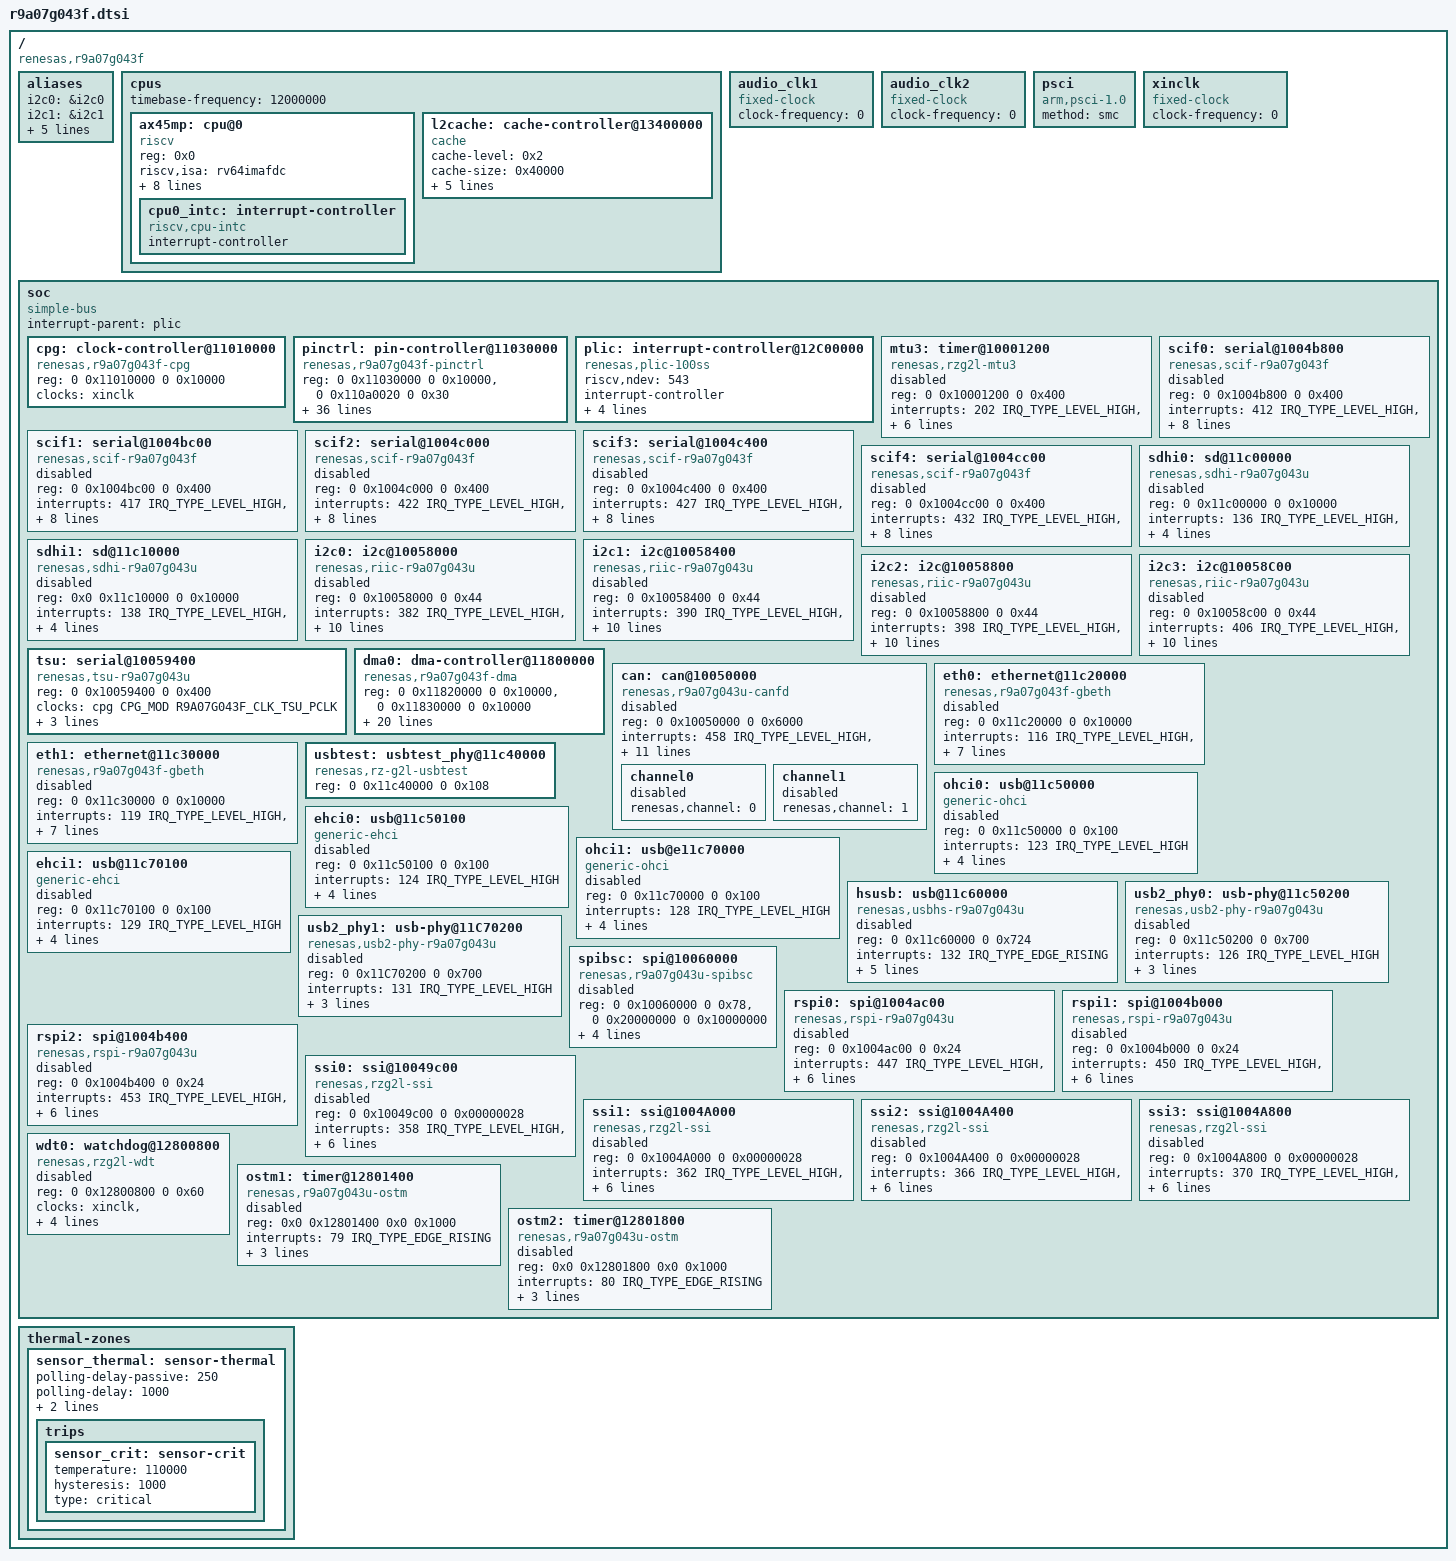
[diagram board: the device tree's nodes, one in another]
// SPDX-License-Identifier: GPL-2.0
/*
 * Device Tree Source for the RZ/Five  series (R9A07G043Fx) SoC
 *
 * Copyright (C) 2021 Renesas Electronics Corp.
 */


#include <dt-bindings/clock/r9a07g043f-cpg-mssr.h>
#include <dt-bindings/interrupt-controller/irq.h>

/ {
	compatible = "renesas,r9a07g043f";
	#address-cells = <2>;
	#size-cells = <2>;

	aliases {
		i2c0 = &i2c0;
		i2c1 = &i2c1;
		i2c2 = &i2c2;
		i2c3 = &i2c3;
		spi0 = &rspi0;
 		spi1 = &rspi1;
		spi2 = &rspi2;
	};

	cpus {
		#address-cells = <1>;
		#size-cells = <0>;
		timebase-frequency = <12000000>;

		ax45mp: cpu@0 {
			compatible = "riscv";
			device_type = "cpu";
			reg = <0x0>;
			status = "okay";
			riscv,isa = "rv64imafdc";
			riscv,priv-major = <0x1>;
			riscv,priv-minor = <0xa>;
			mmu-type = "riscv,sv39";
			i-cache-size = <0x8000>; // 32KB i-cache
			i-cache-line-size = <0x40>; // 64B cache line
			d-cache-size = <0x8000>; // 32KB d-cache
			d-cache-line-size = <0x40>; // 64B cache line
			next-level-cache = <&l2cache>;

			cpu0_intc: interrupt-controller {
				#interrupt-cells = <1>;
				compatible = "riscv,cpu-intc";
				interrupt-controller;
			};
		};

		l2cache: cache-controller@13400000 {
			compatible = "cache";
			cache-level = <0x2>;
			cache-size = <0x40000>; // 256KB l2-cache
			reg = <0x0 0x13400000 0x0 0x100000>; 
			andes,inst-prefetch = <0x0>; // 1
			andes,data-prefetch = <0x0>; // 
			andes,tag-ram-ctl = <0x1 0x0>;
			andes,data-ram-ctl = <0x1 0x0>;
		};

	};
    
	/*
     * The external audio clocks are configured as 0 Hz fixed frequency
     * clocks by default.
     * Boards that provide audio clocks should override them.
     */
	audio_clk1: audio_clk1 {
		compatible = "fixed-clock";
		#clock-cells = <0>;
		clock-frequency = <0>;
	};

	audio_clk2: audio_clk2 {
 		compatible = "fixed-clock";
		#clock-cells = <0>;
		clock-frequency = <0>;
	};

	psci {
		compatible = "arm,psci-1.0", "arm,psci-0.2";
		method = "smc";
	};

	xinclk: xinclk {
		compatible = "fixed-clock";
		#clock-cells = <0>;
		/* This value must be overridden by the board */
		clock-frequency = <0>;
	};

	soc: soc {
		compatible = "simple-bus";
		interrupt-parent = <&plic>;
		#address-cells = <2>;
		#size-cells = <2>;
		ranges;

		cpg: clock-controller@11010000 {
			compatible = "renesas,r9a07g043f-cpg";
			reg = <0 0x11010000 0 0x10000>;
			clocks = <&xinclk>;
			clock-names = "xinclk";
			#clock-cells = <2>;
			#reset-cells = <1>;
			#power-domain-cells = <0>;
		};

		pinctrl: pin-controller@11030000 {
			compatible = "renesas,r9a07g043f-pinctrl";
			reg = <0 0x11030000 0 0x10000>, <0 0x110a0020 0 0x30>;
			gpio-controller;
			#gpio-cells = <2>;
			gpio-ranges = <&pinctrl 0 0 392>;
			clocks = <&cpg CPG_MOD R9A07G043F_CLK_GPIO>;
			interrupt-controller;
			#interrupt-cells = <2>;
			interrupts =	<476 IRQ_TYPE_LEVEL_HIGH>,
					<477 IRQ_TYPE_LEVEL_HIGH>,
					<478 IRQ_TYPE_LEVEL_HIGH>,
					<479 IRQ_TYPE_LEVEL_HIGH>,
					<480 IRQ_TYPE_LEVEL_HIGH>,
					<481 IRQ_TYPE_LEVEL_HIGH>,
					<482 IRQ_TYPE_LEVEL_HIGH>,
					<483 IRQ_TYPE_LEVEL_HIGH>,
					<484 IRQ_TYPE_LEVEL_HIGH>,
					<485 IRQ_TYPE_LEVEL_HIGH>,
					<486 IRQ_TYPE_LEVEL_HIGH>,
					<487 IRQ_TYPE_LEVEL_HIGH>,
					<488 IRQ_TYPE_LEVEL_HIGH>,
					<489 IRQ_TYPE_LEVEL_HIGH>,
					<490 IRQ_TYPE_LEVEL_HIGH>,
					<491 IRQ_TYPE_LEVEL_HIGH>,
					<492 IRQ_TYPE_LEVEL_HIGH>,
					<493 IRQ_TYPE_LEVEL_HIGH>,
					<494 IRQ_TYPE_LEVEL_HIGH>,
					<495 IRQ_TYPE_LEVEL_HIGH>,
					<496 IRQ_TYPE_LEVEL_HIGH>,
					<497 IRQ_TYPE_LEVEL_HIGH>,
					<498 IRQ_TYPE_LEVEL_HIGH>,
					<499 IRQ_TYPE_LEVEL_HIGH>,
					<500 IRQ_TYPE_LEVEL_HIGH>,
					<501 IRQ_TYPE_LEVEL_HIGH>,
					<502 IRQ_TYPE_LEVEL_HIGH>,
					<503 IRQ_TYPE_LEVEL_HIGH>,
					<504 IRQ_TYPE_LEVEL_HIGH>,
					<505 IRQ_TYPE_LEVEL_HIGH>,
					<506 IRQ_TYPE_LEVEL_HIGH>,
					<507 IRQ_TYPE_LEVEL_HIGH>;
		};

		plic: interrupt-controller@12C00000 {
			compatible = "renesas,plic-100ss";
			#interrupt-cells = <2>;
			#address-cells = <0>;
			riscv,ndev = <543>;
			interrupt-controller;
			reg = <0x0 0x12C00000 0 0x400000>,
			      <0x0 0x13000000 0 0x400000>;
			clocks = <&cpg CPG_MOD R9A07G043F_CLK_NCEPLIC>;
			clock-names = "plic100ss";
			interrupts-extended = <
						&cpu0_intc 11 	// for target 0
						&cpu0_intc 9>;	 
		};

		mtu3: timer@10001200 {
			compatible = "renesas,rzg2l-mtu3";
			reg = <0 0x10001200 0 0x400>;
			interrupts =
				<202 IRQ_TYPE_LEVEL_HIGH>,
				<206 IRQ_TYPE_LEVEL_HIGH>,
				<209 IRQ_TYPE_LEVEL_HIGH>,
				<213 IRQ_TYPE_LEVEL_HIGH>;
			interrupt-names = "tgi0a" , "tci0v" , "tgi1a" , "tgi2a";
			clocks = <&cpg CPG_MOD R9A07G043F_CLK_MTU>;
			clock-names = "fck";
			power-domains = <&cpg>;
			resets = <&cpg R9A07G043F_CLK_MTU>;
			status = "disabled";
		};

		scif0: serial@1004b800 {
			compatible = "renesas,scif-r9a07g043f";
			reg = <0 0x1004b800 0 0x400>;
			interrupts =
				<412 IRQ_TYPE_LEVEL_HIGH>,
				<414 IRQ_TYPE_LEVEL_HIGH>,
				<415 IRQ_TYPE_LEVEL_HIGH>,
				<413 IRQ_TYPE_LEVEL_HIGH>,
				<416 IRQ_TYPE_LEVEL_HIGH>,
				<416 IRQ_TYPE_LEVEL_HIGH>;
			clocks = <&cpg CPG_MOD R9A07G043F_CLK_SCIF0>;
			clock-names = "fck";
			resets = <&cpg R9A07G043F_CLK_SCIF0>;
			power-domains = <&cpg>;
			status = "disable";
		};

		scif1: serial@1004bc00 {
			compatible = "renesas,scif-r9a07g043f";
			reg = <0 0x1004bc00 0 0x400>;
			interrupts =
				<417 IRQ_TYPE_LEVEL_HIGH>,
				<419 IRQ_TYPE_LEVEL_HIGH>,
				<420 IRQ_TYPE_LEVEL_HIGH>,
				<418 IRQ_TYPE_LEVEL_HIGH>,
				<421 IRQ_TYPE_LEVEL_HIGH>,
				<421 IRQ_TYPE_LEVEL_HIGH>;
			clocks = <&cpg CPG_MOD R9A07G043F_CLK_SCIF1>;
			clock-names = "fck";
			resets = <&cpg R9A07G043F_CLK_SCIF1>;
			power-domains = <&cpg>;
			status = "disable";
		};

		scif2: serial@1004c000 {
			compatible = "renesas,scif-r9a07g043f";
			reg = <0 0x1004c000 0 0x400>;
			interrupts =
				<422 IRQ_TYPE_LEVEL_HIGH>,
				<424 IRQ_TYPE_LEVEL_HIGH>,
				<425 IRQ_TYPE_LEVEL_HIGH>,
				<423 IRQ_TYPE_LEVEL_HIGH>,
				<426 IRQ_TYPE_LEVEL_HIGH>,
				<426 IRQ_TYPE_LEVEL_HIGH>;
			clocks = <&cpg CPG_MOD R9A07G043F_CLK_SCIF2>;
			clock-names = "fck";
			resets = <&cpg R9A07G043F_CLK_SCIF2>;
			power-domains = <&cpg>;
			status = "disable";
		};

		scif3: serial@1004c400 {
			compatible = "renesas,scif-r9a07g043f";
			reg = <0 0x1004c400 0 0x400>;
			interrupts =
				<427 IRQ_TYPE_LEVEL_HIGH>,
				<429 IRQ_TYPE_LEVEL_HIGH>,
				<430 IRQ_TYPE_LEVEL_HIGH>,
				<428 IRQ_TYPE_LEVEL_HIGH>,
				<431 IRQ_TYPE_LEVEL_HIGH>,
				<431 IRQ_TYPE_LEVEL_HIGH>;
			clocks = <&cpg CPG_MOD R9A07G043F_CLK_SCIF3>;
			clock-names = "fck";
			resets = <&cpg R9A07G043F_CLK_SCIF3>;
			power-domains = <&cpg>;
			status = "disable";
		};

		scif4: serial@1004cc00 {
			compatible = "renesas,scif-r9a07g043f";
			reg = <0 0x1004cc00 0 0x400>;
			interrupts =
				<432 IRQ_TYPE_LEVEL_HIGH>,
				<434 IRQ_TYPE_LEVEL_HIGH>,
				<435 IRQ_TYPE_LEVEL_HIGH>,
				<433 IRQ_TYPE_LEVEL_HIGH>,
				<436 IRQ_TYPE_LEVEL_HIGH>,
				<436 IRQ_TYPE_LEVEL_HIGH>;
			clocks = <&cpg CPG_MOD R9A07G043F_CLK_SCIF4>;
			clock-names = "fck";
			resets = <&cpg R9A07G043F_CLK_SCIF4>;
			power-domains = <&cpg>;
			status = "disable";
		};

		sdhi0: sd@11c00000 {
			compatible = "renesas,sdhi-r9a07g043u",
				     "renesas,rcar-gen3-sdhi";
			reg = <0 0x11c00000 0 0x10000>;
			interrupts = <136 IRQ_TYPE_LEVEL_HIGH>,
				     <137 IRQ_TYPE_LEVEL_HIGH>;
			clocks = <&cpg CPG_MOD R9A07G043F_CLK_SDHI0>;
			resets = <&cpg R9A07G043F_CLK_SDHI0>;
			power-domains = <&cpg>;
			status = "disabled";
		};

		sdhi1: sd@11c10000 {
			compatible = "renesas,sdhi-r9a07g043u",
				     "renesas,rcar-gen3-sdhi";
			reg = <0x0 0x11c10000 0 0x10000>;
			interrupts = <138 IRQ_TYPE_LEVEL_HIGH>,
				     <139 IRQ_TYPE_LEVEL_HIGH>;
			clocks = <&cpg CPG_MOD R9A07G043F_CLK_SDHI1>;
			resets = <&cpg R9A07G043F_CLK_SDHI1>;
			power-domains = <&cpg>;
			status = "disabled";
		};

		i2c0: i2c@10058000 {
			#address-cells = <1>;
			#size-cells = <0>;
			compatible = "renesas,riic-r9a07g043u",
					"renesas,riic-rz";
			reg = <0 0x10058000 0 0x44>;
			interrupts = <382  IRQ_TYPE_LEVEL_HIGH>,
				     <380 IRQ_TYPE_EDGE_RISING>,
				     <381 IRQ_TYPE_EDGE_RISING>,
				     <384 IRQ_TYPE_LEVEL_HIGH>,
				     <385 IRQ_TYPE_LEVEL_HIGH>,
				     <383 IRQ_TYPE_LEVEL_HIGH>,
				     <386 IRQ_TYPE_LEVEL_HIGH>,
				     <387 IRQ_TYPE_LEVEL_HIGH>;
			clocks = <&cpg CPG_MOD R9A07G043F_CLK_I2C0>;
			clock-frequency = <100000>;
			resets = <&cpg R9A07G043F_CLK_I2C0>;
			status = "disabled";
		};

		i2c1: i2c@10058400 {
			#address-cells = <1>;
			#size-cells = <0>;
			compatible = "renesas,riic-r9a07g043u",
					"renesas,riic-rz";
			reg = <0 0x10058400 0 0x44>;
			interrupts = <390  IRQ_TYPE_LEVEL_HIGH>,
				     <388 IRQ_TYPE_EDGE_RISING>,
				     <389 IRQ_TYPE_EDGE_RISING>,
				     <392 IRQ_TYPE_LEVEL_HIGH>,
				     <393 IRQ_TYPE_LEVEL_HIGH>,
				     <391 IRQ_TYPE_LEVEL_HIGH>,
				     <394 IRQ_TYPE_LEVEL_HIGH>,
				     <395 IRQ_TYPE_LEVEL_HIGH>;
			clocks = <&cpg CPG_MOD R9A07G043F_CLK_I2C1>;
			clock-frequency = <100000>;
			resets = <&cpg R9A07G043F_CLK_I2C1>;
			status = "disabled";
		};

		i2c2: i2c@10058800 {
			#address-cells = <1>;
			#size-cells = <0>;
			compatible = "renesas,riic-r9a07g043u",
					"renesas,riic-rz";
			reg = <0 0x10058800 0 0x44>;
			interrupts = <398  IRQ_TYPE_LEVEL_HIGH>,
				     <396 IRQ_TYPE_EDGE_RISING>,
				     <397 IRQ_TYPE_EDGE_RISING>,
				     <400 IRQ_TYPE_LEVEL_HIGH>,
				     <401 IRQ_TYPE_LEVEL_HIGH>,
				     <399 IRQ_TYPE_LEVEL_HIGH>,
				     <402 IRQ_TYPE_LEVEL_HIGH>,
				     <403 IRQ_TYPE_LEVEL_HIGH>;
			clocks = <&cpg CPG_MOD R9A07G043F_CLK_I2C2>;
			clock-frequency = <100000>;
			resets = <&cpg R9A07G043F_CLK_I2C2>;
			status = "disabled";
		};

		i2c3: i2c@10058C00 {
			#address-cells = <1>;
			#size-cells = <0>;
			compatible = "renesas,riic-r9a07g043u",
					"renesas,riic-rz";
			reg = <0 0x10058c00 0 0x44>;
			interrupts = <406  IRQ_TYPE_LEVEL_HIGH>,
				     <404 IRQ_TYPE_EDGE_RISING>,
				     <405 IRQ_TYPE_EDGE_RISING>,
				     <408 IRQ_TYPE_LEVEL_HIGH>,
				     <409 IRQ_TYPE_LEVEL_HIGH>,
				     <407 IRQ_TYPE_LEVEL_HIGH>,
				     <410 IRQ_TYPE_LEVEL_HIGH>,
				     <411 IRQ_TYPE_LEVEL_HIGH>;
			clocks = <&cpg CPG_MOD R9A07G043F_CLK_I2C3>;
			clock-frequency = <100000>;
			resets = <&cpg R9A07G043F_CLK_I2C3>;
			status = "disabled";
		};

		tsu: serial@10059400 {
			compatible = "renesas,tsu-r9a07g043u";
			reg = <0 0x10059400 0 0x400>;
			clocks = <&cpg CPG_MOD R9A07G043F_CLK_TSU_PCLK>;
			resets = <&cpg R9A07G043F_CLK_TSU_PCLK>;
			clock-names = "tsu";
			thermal-cal = <1>;
			#thermal-sensor-cells = <0>;
			power-domains = <&cpg>;
		};

		dma0: dma-controller@11800000 {
			compatible = "renesas,r9a07g043f-dma",
				"renesas,rz-dmac";
			reg =   <0 0x11820000 0 0x10000>,
				<0 0x11830000 0 0x10000>;

			interrupts =
				<173 IRQ_TYPE_EDGE_RISING>,    
				<157 IRQ_TYPE_EDGE_RISING>,
				<158 IRQ_TYPE_EDGE_RISING>,
				<159 IRQ_TYPE_EDGE_RISING>,
				<160 IRQ_TYPE_EDGE_RISING>,
				<161 IRQ_TYPE_EDGE_RISING>,
				<162 IRQ_TYPE_EDGE_RISING>,
				<163 IRQ_TYPE_EDGE_RISING>,
				<164 IRQ_TYPE_EDGE_RISING>,
				<165 IRQ_TYPE_EDGE_RISING>,
				<166 IRQ_TYPE_EDGE_RISING>,
				<167 IRQ_TYPE_EDGE_RISING>,
				<168 IRQ_TYPE_EDGE_RISING>,
				<169 IRQ_TYPE_EDGE_RISING>,
				<170 IRQ_TYPE_EDGE_RISING>,
				<171 IRQ_TYPE_EDGE_RISING>,
				<172 IRQ_TYPE_EDGE_RISING>;
			interrupt-names = "error", 
				"ch0", "ch1", "ch2", "ch3",
				"ch4", "ch5", "ch6", "ch7",
				"ch8", "ch9", "ch10", "ch11",
				"ch12", "ch13", "ch14", "ch15";
			dma-channels = <16>;
			#dma-cells = <1>;
			clocks = <&cpg CPG_MOD R9A07G043F_CLK_DMAC>;
			resets = <&cpg R9A07G043F_CLK_DMAC>;
		};

		can: can@10050000 {
			compatible = "renesas,r9a07g043u-canfd";
			reg = <0 0x10050000 0 0x6000>;
			interrupts =    <458 IRQ_TYPE_LEVEL_HIGH>,
					<454 IRQ_TYPE_LEVEL_HIGH>,
					<460 IRQ_TYPE_LEVEL_HIGH>,
					<455 IRQ_TYPE_LEVEL_HIGH>,
					<461 IRQ_TYPE_LEVEL_HIGH>,
					<456 IRQ_TYPE_LEVEL_HIGH>,
					<457 IRQ_TYPE_LEVEL_HIGH>,
					<459 IRQ_TYPE_LEVEL_HIGH>;

			clocks = <&cpg CPG_MOD R9A07G043F_CLK_CANFD>,
				 <&cpg CPG_CORE R9A07G043F_CLK_P0>;
			clock-names = "fck","canfd";
			resets = <&cpg R9A07G043F_CLK_CANFD>;
			power-dmains = <&cpg>;
			status = "disabled";
			channel0 {
				renesas,channel = <0>;
				status = "disabled";
			};
			channel1 {
				renesas,channel = <1>;
				status = "disabled";
			};
		};

		eth0: ethernet@11c20000 {
			compatible = "renesas,r9a07g043f-gbeth",
				     "renesas,rzg2l-gbeth";
			reg = <0 0x11c20000 0 0x10000>;
			interrupts = <116 IRQ_TYPE_LEVEL_HIGH>,
				     <117 IRQ_TYPE_LEVEL_HIGH>,
				     <118 IRQ_TYPE_LEVEL_HIGH>;
			interrupt-names = "mux", "fil", "arp_ns";
			clocks = <&cpg CPG_MOD R9A07G043F_CLK_ETH0>;
			resets = <&cpg R9A07G043F_CLK_ETH0>;
			power-domains = <&cpg>;
			phy-mode = "rgmii";
			#address-cells = <1>;
			#size-cells = <0>;
			eth-pin-mode-switch = <&pinctrl 0>;
			status = "disabled";
		};

		eth1: ethernet@11c30000 {
			compatible = "renesas,r9a07g043f-gbeth",
				     "renesas,rzg2l-gbeth";
			reg = <0 0x11c30000 0 0x10000>;
			interrupts = <119 IRQ_TYPE_LEVEL_HIGH>,
				     <120 IRQ_TYPE_LEVEL_HIGH>,
				     <121 IRQ_TYPE_LEVEL_HIGH>;
			interrupt-names = "mux", "fil", "arp_ns";
			clocks = <&cpg CPG_MOD R9A07G043F_CLK_ETH1>;
			resets = <&cpg R9A07G043F_CLK_ETH1>;
			power-domains = <&cpg>;
			phy-mode = "rgmii";
			#address-cells = <1>;
			#size-cells = <0>;
			eth-pin-mode-switch = <&pinctrl 1>;
			status = "disabled";
		};

		usbtest: usbtest_phy@11c40000 {
			compatible = "renesas,rz-g2l-usbtest";
			reg = <0 0x11c40000 0 0x108>;
			#phy-cells = <0>;
		};

		ohci0: usb@11c50000 {
			compatible = "generic-ohci";
			reg = <0 0x11c50000 0 0x100>;
			interrupts = <123 IRQ_TYPE_LEVEL_HIGH>;
			clocks = <&cpg CPG_MOD R9A07G043F_CLK_USB0>;
			resets = <&cpg R9A07G043F_CLK_USB0>;
			phys = <&usbtest>, <&usb2_phy0>;
			phy-names = "usb";
			power-domains = <&cpg>;
			status = "disabled";
		};

		ehci0: usb@11c50100 {
			compatible = "generic-ehci";
			reg = <0 0x11c50100 0 0x100>;
			interrupts = <124 IRQ_TYPE_LEVEL_HIGH>;
			clocks = <&cpg CPG_MOD R9A07G043F_CLK_USB0>;
			resets = <&cpg R9A07G043F_CLK_USB0>;
			phys = <&usbtest>, <&usb2_phy0>;
			phy-names = "usb";
			power-domains = <&cpg>;
			status = "disabled";
		};

		ohci1: usb@e11c70000 {
			compatible = "generic-ohci";
			reg = <0 0x11c70000 0 0x100>;
			interrupts = <128 IRQ_TYPE_LEVEL_HIGH>;
			clocks = <&cpg CPG_MOD R9A07G043F_CLK_USB1>;
			resets = <&cpg R9A07G043F_CLK_USB1>;
			phys = <&usbtest>, <&usb2_phy1>;
			phy-names = "usb";
			power-domains = <&cpg>;
			status = "disabled";
		};

		ehci1: usb@11c70100 {
			compatible = "generic-ehci";
			reg = <0 0x11c70100 0 0x100>;
			interrupts = <129 IRQ_TYPE_LEVEL_HIGH>;
			clocks = <&cpg CPG_MOD R9A07G043F_CLK_USB1>;
			resets = <&cpg R9A07G043F_CLK_USB1>;
			phys = <&usbtest>, <&usb2_phy1>;
			phy-names = "usb";
			power-domains = <&cpg>;
			status = "disabled";
		};

		hsusb: usb@11c60000 {
			compatible = "renesas,usbhs-r9a07g043u",
				     "renesas,g2l-usbhs";
			reg = <0 0x11c60000 0 0x724>;
			interrupts = <132 IRQ_TYPE_EDGE_RISING>;
			clocks = <&cpg CPG_MOD R9A07G043F_CLK_USB0>;
			resets = <&cpg R9A07G043F_CLK_USB0>;
			renesas,buswait = <7>;
			phys = <&usbtest>, <&usb2_phy0>;
			phy-names = "usb";
			power-domains = <&cpg>;
			status = "disabled";
		};

		usb2_phy0: usb-phy@11c50200 {
			compatible = "renesas,usb2-phy-r9a07g043u",
				     "renesas,rcar-gen3-usb2-phy";
			reg = <0 0x11c50200 0 0x700>;
			interrupts = <126 IRQ_TYPE_LEVEL_HIGH>;
			clocks = <&cpg CPG_MOD R9A07G043F_CLK_USB0>;
			power-domains = <&cpg>;
			resets = <&cpg R9A07G043F_CLK_USB0>;
			#phy-cells = <0>;
			status = "disabled";
		};

		usb2_phy1: usb-phy@11C70200 {
			compatible = "renesas,usb2-phy-r9a07g043u",
				     "renesas,rcar-gen3-usb2-phy";
			reg = <0 0x11C70200 0 0x700>;
			interrupts = <131 IRQ_TYPE_LEVEL_HIGH>;
			clocks = <&cpg CPG_MOD R9A07G043F_CLK_USB1>;
			power-domains = <&cpg>;
			resets = <&cpg R9A07G043F_CLK_USB1>;
			#phy-cells = <0>;
			status = "disabled";
		};

		spibsc: spi@10060000 {
			compatible = "renesas,r9a07g043u-spibsc";
			reg = <0 0x10060000 0 0x78>,
			      <0 0x20000000 0 0x10000000>;
			interrupts = <73 IRQ_TYPE_LEVEL_HIGH>;
			clocks = <&cpg CPG_MOD R9A07G043F_CLK_SPI>;
			resets = <&cpg R9A07G043F_CLK_SPI>;
			power-domains = <&cpg>;
			#address-cells = <1>;
			#size-cells = <0>;
			status = "disabled";
		};

		rspi0: spi@1004ac00 {
			#address-cells = <1>;
			#size-cells = <0>;
			compatible = "renesas,rspi-r9a07g043u",
				     "renesas,rspi-rz";
			reg = <0 0x1004ac00 0 0x24>;
			interrupts = <447 IRQ_TYPE_LEVEL_HIGH>,
				     <445 IRQ_TYPE_LEVEL_HIGH>,
				     <446 IRQ_TYPE_LEVEL_HIGH>;
			interrupt-names = "error", "rx", "tx";
			clocks = <&cpg CPG_MOD R9A07G043F_CLK_RSPI0>;
			resets = <&cpg R9A07G043F_CLK_RSPI0>;
			power-domains = <&cpg>;
			num-cs = <1>;
			status = "disabled";
		};

		rspi1: spi@1004b000 {
			#address-cells = <1>;
			#size-cells = <0>;
			compatible = "renesas,rspi-r9a07g043u",
				     "renesas,rspi-rz";
			reg = <0 0x1004b000 0 0x24>;
			interrupts = <450 IRQ_TYPE_LEVEL_HIGH>,
				     <448 IRQ_TYPE_LEVEL_HIGH>,
				     <449 IRQ_TYPE_LEVEL_HIGH>;
			interrupt-names = "error", "rx", "tx";
			clocks = <&cpg CPG_MOD R9A07G043F_CLK_RSPI1>;
			resets = <&cpg R9A07G043F_CLK_RSPI1>;
			power-domains = <&cpg>;
			num-cs = <1>;
			status = "disabled";
		};

		rspi2: spi@1004b400 {
			#address-cells = <1>;
			#size-cells = <0>;
			compatible = "renesas,rspi-r9a07g043u",
				     "renesas,rspi-rz";
			reg = <0 0x1004b400 0 0x24>;
			interrupts = <453 IRQ_TYPE_LEVEL_HIGH>,
				     <451 IRQ_TYPE_LEVEL_HIGH>,
				     <452 IRQ_TYPE_LEVEL_HIGH>;
			interrupt-names = "error", "rx", "tx";
			clocks = <&cpg CPG_MOD R9A07G043F_CLK_RSPI2>;
			resets = <&cpg R9A07G043F_CLK_RSPI2>;
			power-domains = <&cpg>;
			num-cs = <1>;
			status = "disabled";
		};

		ssi0: ssi@10049c00 {
			#sound-dai-cells = <0>;
			compatible = "renesas,rzg2l-ssi";
			reg = <0 0x10049c00 0 0x00000028>;
			interrupts = <358 IRQ_TYPE_LEVEL_HIGH>,
				     <359 IRQ_TYPE_EDGE_RISING>,
				     <360 IRQ_TYPE_EDGE_RISING>;
			interrupt-names = "int", "rx", "tx";
			clocks = <&cpg CPG_MOD R9A07G043F_CLK_SSI0> ,
				 <&audio_clk1>,
				 <&audio_clk2>;
			clock-names = "ssi", "audio_clk1", "audio_clk2";
			resets = <&cpg R9A07G043F_CLK_SSI0>;
			power-domains = <&cpg>;
			status = "disabled";
		};

		ssi1: ssi@1004A000 {
			#sound-dai-cells = <0>;
			compatible = "renesas,rzg2l-ssi";
			reg = <0 0x1004A000 0 0x00000028>;
			interrupts = <362 IRQ_TYPE_LEVEL_HIGH>,
				     <363 IRQ_TYPE_EDGE_RISING>,
				     <364 IRQ_TYPE_EDGE_RISING>;
			interrupt-names = "int", "rx", "tx";
			clocks = <&cpg CPG_MOD R9A07G043F_CLK_SSI1>,
				 <&audio_clk1>,
				 <&audio_clk2>;
			clock-names = "ssi", "audio_clk1", "audio_clk2";
			resets = <&cpg R9A07G043F_CLK_SSI1>;
			power-domains = <&cpg>;
			status = "disabled";
		};

		ssi2: ssi@1004A400 {
			#sound-dai-cells = <0>;
			compatible = "renesas,rzg2l-ssi";
			reg = <0 0x1004A400 0 0x00000028>;
			interrupts = <366 IRQ_TYPE_LEVEL_HIGH>,
				     <367 IRQ_TYPE_EDGE_RISING>,
				     <368 IRQ_TYPE_EDGE_RISING>;
			interrupt-names = "int", "rx", "tx";
			clocks = <&cpg CPG_MOD R9A07G043F_CLK_SSI2>,
				 <&audio_clk1>,
				 <&audio_clk2>;
			clock-names = "ssi", "audio_clk1", "audio_clk2";
			resets = <&cpg R9A07G043F_CLK_SSI2>;
			power-domains = <&cpg>;
			status = "disabld";
		};

		ssi3: ssi@1004A800 {
			#sound-dai-cells = <0>;
			compatible = "renesas,rzg2l-ssi";
			reg = <0 0x1004A800 0 0x00000028>;
			interrupts = <370 IRQ_TYPE_LEVEL_HIGH>,
				     <371 IRQ_TYPE_EDGE_RISING>,
				     <372 IRQ_TYPE_EDGE_RISING>;
			interrupt-names = "int", "rx", "tx";
			clocks = <&cpg CPG_MOD R9A07G043F_CLK_SSI3>,
				 <&audio_clk1>,
				 <&audio_clk2>;
			clock-names = "ssi", "audio_clk1", "audio_clk2";
			resets = <&cpg R9A07G043F_CLK_SSI3>;
			power-domains = <&cpg>;
			status = "disabled";
		};

		wdt0: watchdog@12800800 {
			compatible = "renesas,rzg2l-wdt";
			reg = <0 0x12800800 0 0x60>;
			clocks = <&xinclk>,
				 <&cpg CPG_MOD R9A07G043F_CLK_WDT0>;
			interrupts = <81 IRQ_TYPE_LEVEL_HIGH>,
				     <82 IRQ_TYPE_LEVEL_HIGH>;
			resets = <&cpg R9A07G043F_CLK_WDT0>;
			status = "disabled";
		};

		ostm1: timer@12801400 {
			compatible = "renesas,r9a07g043u-ostm";
			reg = <0x0 0x12801400 0x0 0x1000>;
			interrupts = <79 IRQ_TYPE_EDGE_RISING>;
			clocks = <&cpg CPG_MOD R9A07G043F_CLK_OSTM1>;
			clock-names = "pclk";
			power-domains = <&cpg>;
			resets = <&cpg R9A07G043F_CLK_OSTM1>;
			status = "disabled";
		};

		ostm2: timer@12801800 {
			compatible = "renesas,r9a07g043u-ostm";
			reg = <0x0 0x12801800 0x0 0x1000>;
			interrupts = <80 IRQ_TYPE_EDGE_RISING>;
			clocks = <&cpg CPG_MOD R9A07G043F_CLK_OSTM2>;
			clock-names = "pclk";
			power-domains = <&cpg>;
			resets = <&cpg R9A07G043F_CLK_OSTM2>;
			status = "disabled";
		};
	};

	thermal-zones {
		sensor_thermal: sensor-thermal {
			polling-delay-passive = <250>;
			polling-delay = <1000>;
			sustainable-power = <3874>;
			thermal-sensors = <&tsu 0>;

			trips {
				sensor_crit: sensor-crit {
				temperature = <110000>;
				hysteresis = <1000>;
				type = "critical";
				};
			};
		};
	};
};

